# iospear310 register map
Registers are 32-bit, access not given, no defined reset value unless marked. A register's access mark holds for its fields unless they carry their own. Addresses are absolute; registers are grouped by the start of their names; [hi:lo] are bit positions; {n}, {i} and the like mark numbered series; 'fields as' and 'values as' point back to an identical list.

## ADC
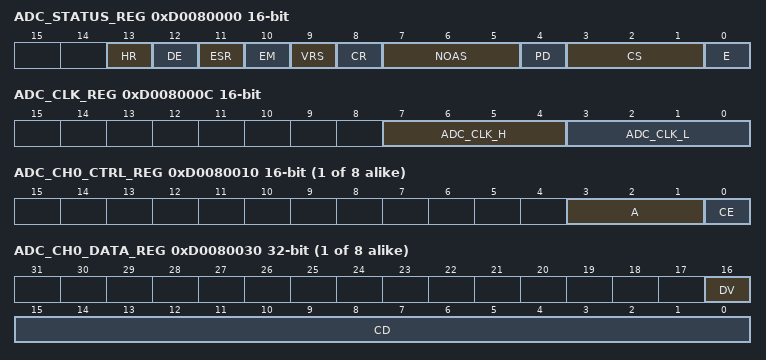
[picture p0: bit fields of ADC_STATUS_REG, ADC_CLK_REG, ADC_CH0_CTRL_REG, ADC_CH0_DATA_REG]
0xD0080000 ADC_STATUS_REG 16-bit
  [13] HR, [12] DE, [11] ESR, [10] EM, [9] VRS, [8] CR, [7:5] NOAS, [4] PD, [3:1] CS, [0] E
0xD0080004 ADC_AVERAGE_REG 16-bit
  [9:0] CD
0xD0080008 ADC_SCAN_RATE_REG
0xD008000C ADC_CLK_REG 16-bit
  [7:4] ADC_CLK_H, [3:0] ADC_CLK_L
{0xD0080010+4i} ADC_CH{i}_CTRL_REG 16-bit (i=0..7)
  [3:1] A, [0] CE
{0xD0080030+4i} ADC_CH{i}_DATA_REG (i=0..7)
  [16] DV, [15:0] CD

## MACB0
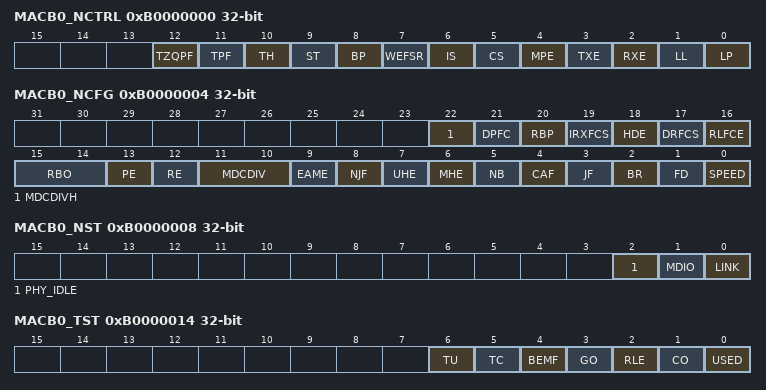
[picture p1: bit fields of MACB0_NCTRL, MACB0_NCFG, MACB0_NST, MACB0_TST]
0xB0000000 MACB0_NCTRL
  [12] TZQPF, [11] TPF, [10] TH, [9] ST, [8] BP, [7] WEFSR, [6] IS, [5] CS, [4] MPE, [3] TXE, [2] RXE, [1] LL, [0] LP
0xB0000004 MACB0_NCFG
  [22] MDCDIVH, [21] DPFC, [20] RBP, [19] IRXFCS, [18] HDE, [17] DRFCS, [16] RLFCE, [15:14] RBO, [13] PE, [12] RE, [11:10] MDCDIV, [9] EAME, [8] NJF, [7] UHE, [6] MHE, [5] NB, [4] CAF, [3] JF, [2] BR, [1] FD, [0] SPEED
0xB0000008 MACB0_NST
  [2] PHY_IDLE, [1] MDIO, [0] LINK
0xB0000014 MACB0_TST
  [6] TU, [5] TC, [4] BEMF, [3] GO, [2] RLE, [1] CO, [0] USED
0xB0000018 MACB0_RBQP
0xB000001C MACB0_TBQP
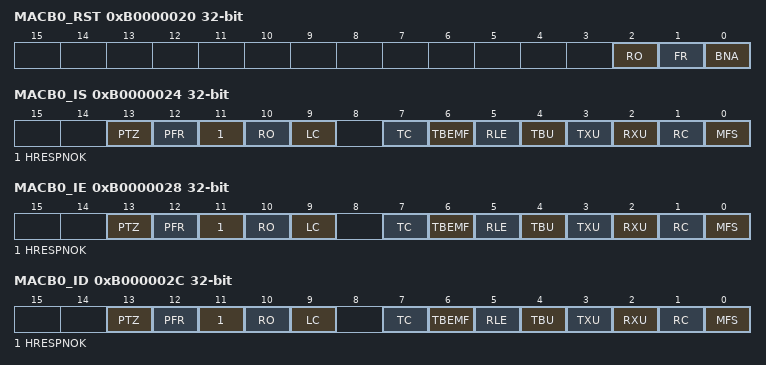
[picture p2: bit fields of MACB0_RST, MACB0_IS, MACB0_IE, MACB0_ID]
0xB0000020 MACB0_RST
  [2] RO, [1] FR, [0] BNA
0xB0000024 MACB0_IS
  [13] PTZ, [12] PFR, [11] HRESPNOK, [10] RO, [9] LC, [7] TC, [6] TBEMF, [5] RLE, [4] TBU, [3] TXU, [2] RXU, [1] RC, [0] MFS
0xB0000028 MACB0_IE
  fields as MACB0_IS
0xB000002C MACB0_ID
  fields as MACB0_IS
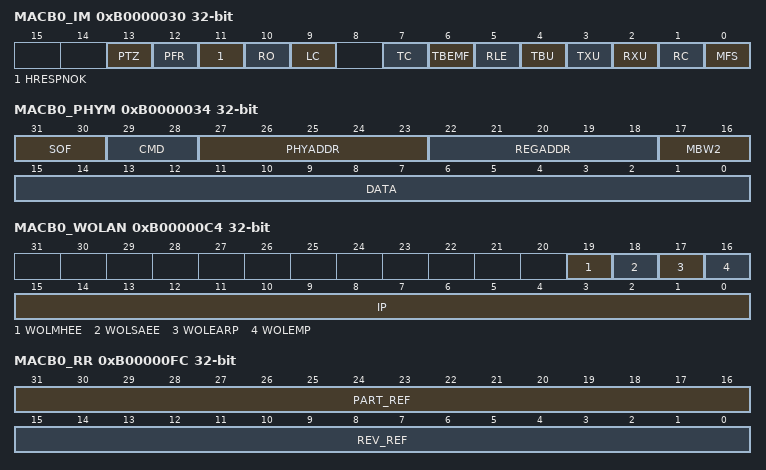
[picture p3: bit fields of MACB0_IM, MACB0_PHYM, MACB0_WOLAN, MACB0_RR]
0xB0000030 MACB0_IM
  fields as MACB0_IS
0xB0000034 MACB0_PHYM
  [31:30] SOF, [29:28] CMD, [27:23] PHYADDR, [22:18] REGADDR, [17:16] MBW2, [15:0] DATA
0xB0000038 MACB0_PT
  [15:0] PT
0xB000003C MACB0_PFR
  [15:0] FRAME_CNTR
0xB0000040 MACB0_FT
  [15:0] FRAME_CNTR
0xB0000044 MACB0_SCF
  [15:0] FRAME_CNTR
0xB0000048 MACB0_MCF
  [15:0] FRAME_CNTR
0xB000004C MACB0_FR
  [23:0] FRAME_CNTR
0xB0000050 MACB0_FCSE
  [7:0] FCSE
0xB0000054 MACB0_AE
  [7:0] AE
0xB0000058 MACB0_DTF
  [15:0] DTF
0xB000005C MACB0_LC
  [7:0] LC
0xB0000060 MACB0_EC
  [7:0] EC
0xB0000064 MACB0_TUE
  [7:0] TUE
0xB0000068 MACB0_CSE
  [7:0] CSE
0xB000006C MACB0_RRE
  [15:0] RRE
0xB0000070 MACB0_ROE
  [7:0] ROE
0xB0000074 MACB0_RSE
  [7:0] REE
0xB0000078 MACB0_ELE
  [7:0] ELE
0xB000007C MACB0_RJ
  [7:0] RJ
0xB0000080 MACB0_UF
  [7:0] UF
0xB0000084 MACB0_SEQTE
  [7:0] SQETE
0xB0000088 MACB0_RLFM
  [7:0] RLFM
0xB000008C MACB0_TPF
  [15:0] TPF
0xB0000090 MACB0_HRB
0xB0000094 MACB0_HRT
{0xB0000090+8i} MACB0_SAB{i} (i=1..4)
{0xB0000094+8i} MACB0_SAT{i} (i=1..4)
  [15:0] ADDR
0xB00000B8 MACB0_TIDC
  [15:0] ID
0xB00000BC MACB0_TPQ
  [15:0] TPQ
0xB00000C4 MACB0_WOLAN
  [19] WOLMHEE, [18] WOLSAEE, [17] WOLEARP, [16] WOLEMP, [15:0] IP
0xB00000FC MACB0_RR
  [31:16] PART_REF, [15:0] REV_REF

## MACB1
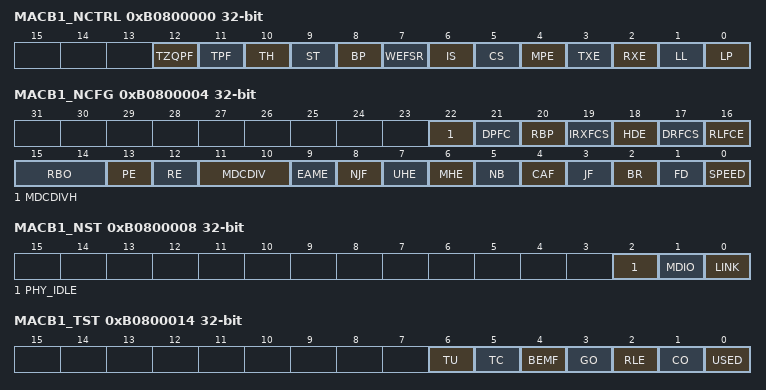
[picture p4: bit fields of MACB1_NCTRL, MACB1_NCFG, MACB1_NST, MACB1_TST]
0xB0800000 MACB1_NCTRL
  [12] TZQPF, [11] TPF, [10] TH, [9] ST, [8] BP, [7] WEFSR, [6] IS, [5] CS, [4] MPE, [3] TXE, [2] RXE, [1] LL, [0] LP
0xB0800004 MACB1_NCFG
  [22] MDCDIVH, [21] DPFC, [20] RBP, [19] IRXFCS, [18] HDE, [17] DRFCS, [16] RLFCE, [15:14] RBO, [13] PE, [12] RE, [11:10] MDCDIV, [9] EAME, [8] NJF, [7] UHE, [6] MHE, [5] NB, [4] CAF, [3] JF, [2] BR, [1] FD, [0] SPEED
0xB0800008 MACB1_NST
  [2] PHY_IDLE, [1] MDIO, [0] LINK
0xB0800014 MACB1_TST
  [6] TU, [5] TC, [4] BEMF, [3] GO, [2] RLE, [1] CO, [0] USED
0xB0800018 MACB1_RBQP
0xB080001C MACB1_TBQP
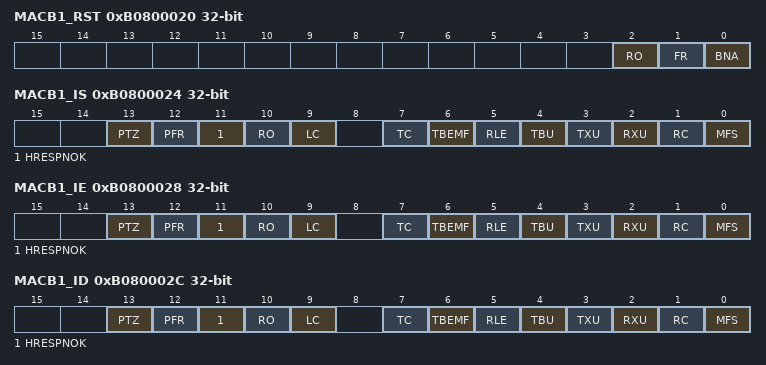
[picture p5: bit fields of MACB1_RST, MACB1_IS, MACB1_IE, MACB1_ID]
0xB0800020 MACB1_RST
  [2] RO, [1] FR, [0] BNA
0xB0800024 MACB1_IS
  [13] PTZ, [12] PFR, [11] HRESPNOK, [10] RO, [9] LC, [7] TC, [6] TBEMF, [5] RLE, [4] TBU, [3] TXU, [2] RXU, [1] RC, [0] MFS
0xB0800028 MACB1_IE
  fields as MACB1_IS
0xB080002C MACB1_ID
  fields as MACB1_IS
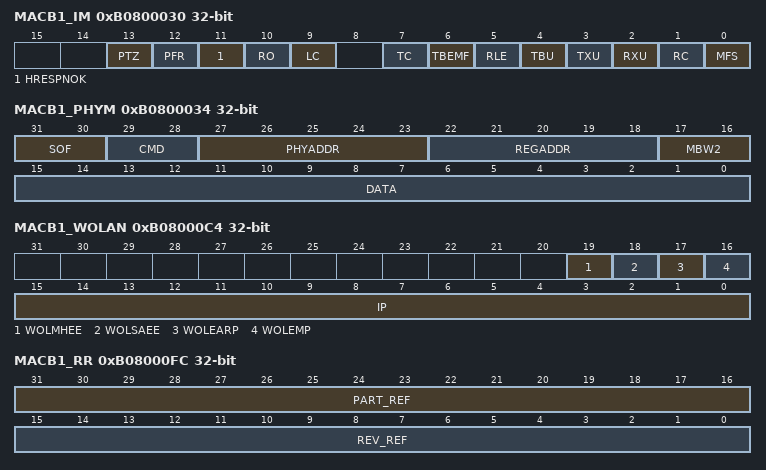
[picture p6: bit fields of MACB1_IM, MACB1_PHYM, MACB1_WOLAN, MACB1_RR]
0xB0800030 MACB1_IM
  fields as MACB1_IS
0xB0800034 MACB1_PHYM
  [31:30] SOF, [29:28] CMD, [27:23] PHYADDR, [22:18] REGADDR, [17:16] MBW2, [15:0] DATA
0xB0800038 MACB1_PT
  [15:0] PT
0xB080003C MACB1_PFR
  [15:0] FRAME_CNTR
0xB0800040 MACB1_FT
  [15:0] FRAME_CNTR
0xB0800044 MACB1_SCF
  [15:0] FRAME_CNTR
0xB0800048 MACB1_MCF
  [15:0] FRAME_CNTR
0xB080004C MACB1_FR
  [23:0] FRAME_CNTR
0xB0800050 MACB1_FCSE
  [7:0] FCSE
0xB0800054 MACB1_AE
  [7:0] AE
0xB0800058 MACB1_DTF
  [15:0] DTF
0xB080005C MACB1_LC
  [7:0] LC
0xB0800060 MACB1_EC
  [7:0] EC
0xB0800064 MACB1_TUE
  [7:0] TUE
0xB0800068 MACB1_CSE
  [7:0] CSE
0xB080006C MACB1_RRE
  [15:0] RRE
0xB0800070 MACB1_ROE
  [7:0] ROE
0xB0800074 MACB1_RSE
  [7:0] REE
0xB0800078 MACB1_ELE
  [7:0] ELE
0xB080007C MACB1_RJ
  [7:0] RJ
0xB0800080 MACB1_UF
  [7:0] UF
0xB0800084 MACB1_SEQTE
  [7:0] SQETE
0xB0800088 MACB1_RLFM
  [7:0] RLFM
0xB080008C MACB1_TPF
  [15:0] TPF
0xB0800090 MACB1_HRB
0xB0800094 MACB1_HRT
{0xB0800090+8i} MACB1_SAB{i} (i=1..4)
{0xB0800094+8i} MACB1_SAT{i} (i=1..4)
  [15:0] ADDR
0xB08000B8 MACB1_TIDC
  [15:0] ID
0xB08000BC MACB1_TPQ
  [15:0] TPQ
0xB08000C4 MACB1_WOLAN
  [19] WOLMHEE, [18] WOLSAEE, [17] WOLEARP, [16] WOLEMP, [15:0] IP
0xB08000FC MACB1_RR
  [31:16] PART_REF, [15:0] REV_REF
